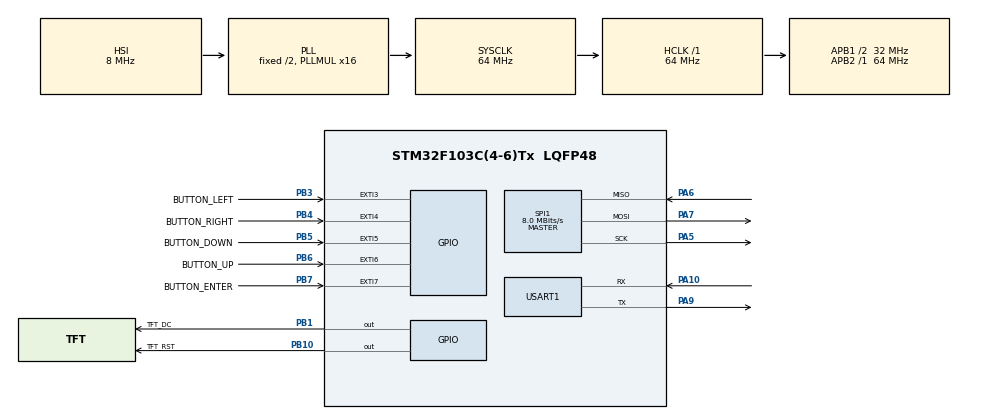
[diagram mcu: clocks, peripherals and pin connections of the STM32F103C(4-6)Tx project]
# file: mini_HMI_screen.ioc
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Dma.Request0=USART1_RX
Dma.Request1=SPI1_TX
Dma.SPI1_TX.1.Direction=DMA_MEMORY_TO_PERIPH
Dma.SPI1_TX.1.Instance=DMA1_Channel3
Dma.SPI1_TX.1.MemDataAlignment=DMA_MDATAALIGN_BYTE
Dma.SPI1_TX.1.MemInc=DMA_MINC_ENABLE
Dma.SPI1_TX.1.Mode=DMA_NORMAL
Dma.SPI1_TX.1.PeriphDataAlignment=DMA_PDATAALIGN_BYTE
Dma.SPI1_TX.1.PeriphInc=DMA_PINC_DISABLE
Dma.SPI1_TX.1.Priority=DMA_PRIORITY_LOW
Dma.USART1_RX.0.Direction=DMA_PERIPH_TO_MEMORY
Dma.USART1_RX.0.Instance=DMA1_Channel5
Dma.USART1_RX.0.MemDataAlignment=DMA_MDATAALIGN_BYTE
Dma.USART1_RX.0.MemInc=DMA_MINC_ENABLE
Dma.USART1_RX.0.Mode=DMA_NORMAL
Dma.USART1_RX.0.PeriphDataAlignment=DMA_PDATAALIGN_BYTE
Dma.USART1_RX.0.PeriphInc=DMA_PINC_DISABLE
Dma.USART1_RX.0.Priority=DMA_PRIORITY_LOW
Mcu.Family=STM32F1
Mcu.Name=STM32F103C(4-6)Tx
Mcu.Package=LQFP48
NVIC.DMA1_Channel3_IRQn=true\:0\:0\:false\:false\:true\:false\:true
NVIC.DMA1_Channel5_IRQn=true\:0\:0\:false\:true\:true\:1\:false\:true
NVIC.EXTI3_IRQn=true\:0\:0\:false\:true\:true\:5\:true\:true
NVIC.EXTI4_IRQn=true\:0\:0\:false\:true\:true\:4\:true\:true
NVIC.EXTI9_5_IRQn=true\:0\:0\:false\:true\:true\:3\:true\:true
NVIC.PriorityGroup=NVIC_PRIORITYGROUP_4
NVIC.USART1_IRQn=true\:0\:0\:false\:true\:true\:2\:true\:true
PA10.Mode=Asynchronous
PA10.Signal=USART1_RX
PA13.Mode=Serial_Wire
PA13.Signal=SYS_JTMS-SWDIO
PA14.Mode=Serial_Wire
PA14.Signal=SYS_JTCK-SWCLK
PA5.Mode=Full_Duplex_Master
PA5.Signal=SPI1_SCK
PA6.Mode=Full_Duplex_Master
PA6.Signal=SPI1_MISO
PA7.Mode=Full_Duplex_Master
PA7.Signal=SPI1_MOSI
PA9.Mode=Asynchronous
PA9.Signal=USART1_TX
PB1.GPIO_Label=TFT_DC
PB1.Signal=GPIO_Output
PB10.GPIO_Label=TFT_RST
PB10.Signal=GPIO_Output
PB3.GPIO_Label=BUTTON_LEFT
PB3.GPIO_ModeDefaultEXTI=GPIO_MODE_IT_FALLING
PB3.Signal=GPXTI3
PB4.GPIO_Label=BUTTON_RIGHT
PB4.GPIO_ModeDefaultEXTI=GPIO_MODE_IT_FALLING
PB4.Signal=GPXTI4
PB5.GPIO_Label=BUTTON_DOWN
PB5.GPIO_ModeDefaultEXTI=GPIO_MODE_IT_FALLING
PB5.Signal=GPXTI5
PB6.GPIO_Label=BUTTON_UP
PB6.GPIO_ModeDefaultEXTI=GPIO_MODE_IT_FALLING
PB6.Signal=GPXTI6
PB7.GPIO_Label=BUTTON_ENTER
PB7.GPIO_ModeDefaultEXTI=GPIO_MODE_IT_FALLING
PB7.Signal=GPXTI7
ProjectManager.HeapSize=0x200
ProjectManager.StackSize=0x400
ProjectManager.TargetToolchain=STM32CubeIDE
RCC.AHBFreq_Value=64000000
RCC.APB1CLKDivider=RCC_HCLK_DIV2
RCC.APB1Freq_Value=32000000
RCC.APB1TimFreq_Value=64000000
RCC.APB2Freq_Value=64000000
RCC.APB2TimFreq_Value=64000000
RCC.HCLKFreq_Value=64000000
RCC.PLLMUL=RCC_PLL_MUL16
RCC.SYSCLKFreq_VALUE=64000000
RCC.SYSCLKSource=RCC_SYSCLKSOURCE_PLLCLK
RCC.USBFreq_Value=64000000
SPI1.BaudRatePrescaler=SPI_BAUDRATEPRESCALER_8
SPI1.CalculateBaudRate=8.0 MBits/s
SPI1.Direction=SPI_DIRECTION_2LINES
SPI1.Mode=SPI_MODE_MASTER
SPI1.VirtualType=VM_MASTER
USART1.VirtualMode=VM_ASYNC
board=custom

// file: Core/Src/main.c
/* USER CODE BEGIN Header */
/**
 ******************************************************************************
 * @file           : main.c
 * @brief          : Main program body
 ******************************************************************************
 * @attention
 *
 * <h2><center>&copy; Copyright (c) 2022 STMicroelectronics.
 * All rights reserved.</center></h2>
 *
 * This software component is licensed by ST under BSD 3-Clause license,
 * the "License"; You may not use this file except in compliance with the
 * License. You may obtain a copy of the License at:
 *                        opensource.org/licenses/BSD-3-Clause
 *
 ******************************************************************************
 */
/* USER CODE END Header */
#include "main.h"
#include "dma.h"
#include "spi.h"
#include "usart.h"
#include "gpio.h"

/* USER CODE BEGIN Includes */
#include "hmi.h"
/* USER CODE END Includes */

/* USER CODE BEGIN PV */
volatile uint8_t response_received = 1;
/* USER CODE END PV */

void SystemClock_Config(void);
static void MX_NVIC_Init(void);

int main(void)
{

  /* MCU Configuration--------------------------------------------------------*/

  /* Reset of all peripherals, Initializes the Flash interface and the Systick. */
  HAL_Init();

  /* Configure the system clock */
  SystemClock_Config();

  /* Initialize all configured peripherals */
  MX_GPIO_Init();
  MX_SPI1_Init();
  MX_DMA_Init();
  MX_USART1_UART_Init();

  /* Initialize interrupts */
  MX_NVIC_Init();
  /* USER CODE BEGIN 2 */

  hmi_main();

  /* USER CODE END 2 */

  /* Infinite loop */
  while (1) {

  }
}

void SystemClock_Config(void)
{
  RCC_OscInitTypeDef RCC_OscInitStruct = {0};
  RCC_ClkInitTypeDef RCC_ClkInitStruct = {0};

  /** Initializes the RCC Oscillators according to the specified parameters
  * in the RCC_OscInitTypeDef structure.
  */
  RCC_OscInitStruct.OscillatorType = RCC_OSCILLATORTYPE_HSI;
  RCC_OscInitStruct.HSIState = RCC_HSI_ON;
  RCC_OscInitStruct.HSICalibrationValue = RCC_HSICALIBRATION_DEFAULT;
  RCC_OscInitStruct.PLL.PLLState = RCC_PLL_ON;
  RCC_OscInitStruct.PLL.PLLSource = RCC_PLLSOURCE_HSI_DIV2;
  RCC_OscInitStruct.PLL.PLLMUL = RCC_PLL_MUL16;
  if (HAL_RCC_OscConfig(&RCC_OscInitStruct) != HAL_OK)
  {
    Error_Handler();
  }
  /** Initializes the CPU, AHB and APB buses clocks
  */
  RCC_ClkInitStruct.ClockType = RCC_CLOCKTYPE_HCLK|RCC_CLOCKTYPE_SYSCLK
                              |RCC_CLOCKTYPE_PCLK1|RCC_CLOCKTYPE_PCLK2;
  RCC_ClkInitStruct.SYSCLKSource = RCC_SYSCLKSOURCE_PLLCLK;
  RCC_ClkInitStruct.AHBCLKDivider = RCC_SYSCLK_DIV1;
  RCC_ClkInitStruct.APB1CLKDivider = RCC_HCLK_DIV2;
  RCC_ClkInitStruct.APB2CLKDivider = RCC_HCLK_DIV1;

  if (HAL_RCC_ClockConfig(&RCC_ClkInitStruct, FLASH_LATENCY_2) != HAL_OK)
  {
    Error_Handler();
  }
}

/**
  * @brief NVIC Configuration.
  * @retval None
  */
static void MX_NVIC_Init(void)
{
  /* DMA1_Channel5_IRQn interrupt configuration */
  HAL_NVIC_SetPriority(DMA1_Channel5_IRQn, 0, 0);
  HAL_NVIC_EnableIRQ(DMA1_Channel5_IRQn);
  /* USART1_IRQn interrupt configuration */
  HAL_NVIC_SetPriority(USART1_IRQn, 0, 0);
  HAL_NVIC_EnableIRQ(USART1_IRQn);
  /* EXTI9_5_IRQn interrupt configuration */
  HAL_NVIC_SetPriority(EXTI9_5_IRQn, 0, 0);
  HAL_NVIC_EnableIRQ(EXTI9_5_IRQn);
  /* EXTI4_IRQn interrupt configuration */
  HAL_NVIC_SetPriority(EXTI4_IRQn, 0, 0);
  HAL_NVIC_EnableIRQ(EXTI4_IRQn);
  /* EXTI3_IRQn interrupt configuration */
  HAL_NVIC_SetPriority(EXTI3_IRQn, 0, 0);
  HAL_NVIC_EnableIRQ(EXTI3_IRQn);
}

void Error_Handler(void)
{
  __disable_irq();
  while (1) {
  }
}

#ifdef  USE_FULL_ASSERT
/**
  * @brief  Reports the name of the source file and the source line number
  *         where the assert_param error has occurred.
  * @param  file: pointer to the source file name
  * @param  line: assert_param error line source number
  * @retval None
  */
void assert_failed(uint8_t *file, uint32_t line)
{
  /* USER CODE BEGIN 6 */
  /* User can add his own implementation to report the file name and line
     number,
     ex: printf("Wrong parameters value: file %s on line %d\r\n", file, line) */
  /* USER CODE END 6 */
}
#endif /* USE_FULL_ASSERT */

/************************ (C) COPYRIGHT STMicroelectronics *****END OF FILE****/
